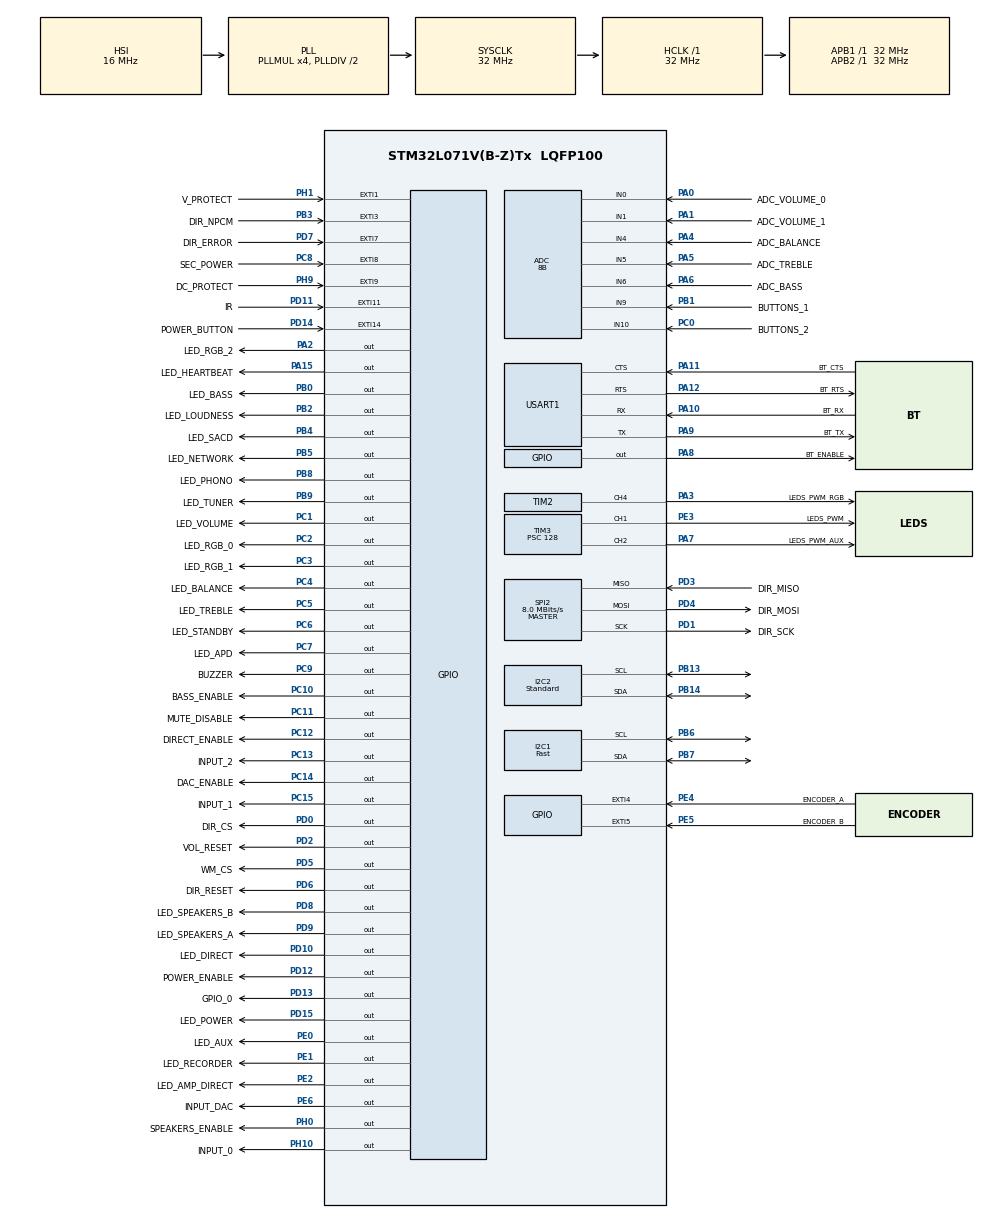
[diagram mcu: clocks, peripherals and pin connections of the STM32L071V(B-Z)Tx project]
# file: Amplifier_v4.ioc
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ADC.ClockPrescaler=ADC_CLOCK_SYNC_PCLK_DIV4
ADC.LowPowerAutoWait=ENABLE
ADC.Overrun=ADC_OVR_DATA_OVERWRITTEN
ADC.OversamplingMode=DISABLE
ADC.Resolution=ADC_RESOLUTION_8B
ADC.SamplingTime=ADC_SAMPLETIME_79CYCLES_5
I2C1.Analog_Filter=I2C_ANALOGFILTER_DISABLE
I2C1.I2C_Speed_Mode=I2C_Fast
I2C1.Timing=0x00301139
I2C2.Analog_Filter=I2C_ANALOGFILTER_ENABLE
I2C2.I2C_Speed_Mode=I2C_Standard
I2C2.Timing=0x00707CBB
Mcu.Family=STM32L0
Mcu.Name=STM32L071V(B-Z)Tx
Mcu.Package=LQFP100
NVIC.ADC1_COMP_IRQn=true\:2\:0\:true\:false\:true\:true\:true
NVIC.EXTI0_1_IRQn=true\:0\:0\:true\:false\:true\:true\:true
NVIC.EXTI2_3_IRQn=true\:0\:0\:false\:false\:true\:true\:true
NVIC.EXTI4_15_IRQn=true\:0\:0\:true\:false\:true\:true\:true
NVIC.TIM6_IRQn=true\:1\:0\:true\:false\:true\:true\:true
NVIC.TIM7_IRQn=true\:1\:0\:true\:false\:true\:true\:true
NVIC.USART1_IRQn=true\:1\:0\:true\:false\:true\:true\:true
PA0.GPIO_Label=ADC_VOLUME_0
PA0.Mode=IN0
PA0.Signal=ADC_IN0
PA1.GPIO_Label=ADC_VOLUME_1
PA1.Mode=IN1
PA1.Signal=ADC_IN1
PA10.GPIO_Label=BT_RX
PA10.Mode=Asynchronous
PA10.Signal=USART1_RX
PA11.GPIO_Label=BT_CTS
PA11.Mode=CTS_RTS
PA11.Signal=USART1_CTS
PA12.GPIO_Label=BT_RTS
PA12.Mode=CTS_RTS
PA12.Signal=USART1_RTS
PA13.Mode=Serial_Wire
PA13.Signal=SYS_SWDIO
PA14.Mode=Serial_Wire
PA14.Signal=SYS_SWCLK
PA15.GPIO_Label=LED_HEARTBEAT
PA15.Signal=GPIO_Output
PA2.GPIO_Label=LED_RGB_2
PA2.Signal=GPIO_Output
PA3.GPIO_Label=LEDS_PWM_RGB
PA3.Signal=S_TIM2_CH4
PA4.GPIO_Label=ADC_BALANCE
PA4.Mode=IN4
PA4.Signal=ADC_IN4
PA5.GPIO_Label=ADC_TREBLE
PA5.Mode=IN5
PA5.Signal=ADC_IN5
PA6.GPIO_Label=ADC_BASS
PA6.Mode=IN6
PA6.Signal=ADC_IN6
PA7.GPIO_Label=LEDS_PWM_AUX
PA7.Signal=S_TIM3_CH2
PA8.GPIO_Label=BT_ENABLE
PA8.PinState=GPIO_PIN_SET
PA8.Signal=GPIO_Output
PA9.GPIO_Label=BT_TX
PA9.Mode=Asynchronous
PA9.Signal=USART1_TX
PB0.GPIO_Label=LED_BASS
PB0.Signal=GPIO_Output
PB1.GPIO_Label=BUTTONS_1
PB1.Mode=IN9
PB1.Signal=ADC_IN9
PB13.Mode=I2C
PB13.Signal=I2C2_SCL
PB14.Mode=I2C
PB14.Signal=I2C2_SDA
PB2.GPIO_Label=LED_LOUDNESS
PB2.Signal=GPIO_Output
PB3.GPIO_Label=DIR_NPCM
PB3.GPIO_ModeDefaultEXTI=GPIO_MODE_IT_RISING_FALLING
PB3.Signal=GPXTI3
PB4.GPIO_Label=LED_SACD
PB4.Signal=GPIO_Output
PB5.GPIO_Label=LED_NETWORK
PB5.Signal=GPIO_Output
PB6.Mode=I2C
PB6.Signal=I2C1_SCL
PB7.Mode=I2C
PB7.Signal=I2C1_SDA
PB8.GPIO_Label=LED_PHONO
PB8.Signal=GPIO_Output
PB9.GPIO_Label=LED_TUNER
PB9.Signal=GPIO_Output
PC0.GPIO_Label=BUTTONS_2
PC0.Mode=IN10
PC0.Signal=ADC_IN10
PC1.GPIO_Label=LED_VOLUME
PC1.Signal=GPIO_Output
PC10.GPIO_Label=BASS_ENABLE
PC10.Signal=GPIO_Output
PC11.GPIO_Label=MUTE_DISABLE
PC11.Signal=GPIO_Output
PC12.GPIO_Label=DIRECT_ENABLE
PC12.Signal=GPIO_Output
PC13.GPIO_Label=INPUT_2
PC13.Signal=GPIO_Output
PC14-OSC32_IN.GPIO_Label=DAC_ENABLE
PC14-OSC32_IN.Signal=GPIO_Output
PC15-OSC32_OUT.GPIO_Label=INPUT_1
PC15-OSC32_OUT.Signal=GPIO_Output
PC2.GPIO_Label=LED_RGB_0
PC2.Signal=GPIO_Output
PC3.GPIO_Label=LED_RGB_1
PC3.Signal=GPIO_Output
PC4.GPIO_Label=LED_BALANCE
PC4.Signal=GPIO_Output
PC5.GPIO_Label=LED_TREBLE
PC5.Signal=GPIO_Output
PC6.GPIO_Label=LED_STANDBY
PC6.Signal=GPIO_Output
PC7.GPIO_Label=LED_APD
PC7.Signal=GPIO_Output
PC8.GPIO_Label=SEC_POWER
PC8.Signal=GPXTI8
PC9.GPIO_Label=BUZZER
PC9.Signal=GPIO_Output
PD0.GPIO_Label=DIR_CS
PD0.Signal=GPIO_Output
PD1.GPIO_Label=DIR_SCK
PD1.Mode=Full_Duplex_Master
PD1.Signal=SPI2_SCK
PD10.GPIO_Label=LED_DIRECT
PD10.Signal=GPIO_Output
PD11.GPIO_Label=IR
PD11.GPIO_ModeDefaultEXTI=GPIO_MODE_IT_FALLING
PD11.Signal=GPXTI11
PD12.GPIO_Label=POWER_ENABLE
PD12.Signal=GPIO_Output
PD13.GPIO_Label=GPIO_0
PD13.Signal=GPIO_Output
PD14.GPIO_Label=POWER_BUTTON
PD14.GPIO_ModeDefaultEXTI=GPIO_MODE_IT_RISING_FALLING
PD14.Signal=GPXTI14
PD15.GPIO_Label=LED_POWER
PD15.Signal=GPIO_Output
PD2.GPIO_Label=VOL_RESET
PD2.Signal=GPIO_Output
PD3.GPIO_Label=DIR_MISO
PD3.Mode=Full_Duplex_Master
PD3.Signal=SPI2_MISO
PD4.GPIO_Label=DIR_MOSI
PD4.Mode=Full_Duplex_Master
PD4.Signal=SPI2_MOSI
PD5.GPIO_Label=WM_CS
PD5.Signal=GPIO_Output
PD6.GPIO_Label=DIR_RESET
PD6.Signal=GPIO_Output
PD7.GPIO_Label=DIR_ERROR
PD7.Signal=GPXTI7
PD8.GPIO_Label=LED_SPEAKERS_B
PD8.Signal=GPIO_Output
PD9.GPIO_Label=LED_SPEAKERS_A
PD9.Signal=GPIO_Output
PE0.GPIO_Label=LED_AUX
PE0.Signal=GPIO_Output
PE1.GPIO_Label=LED_RECORDER
PE1.Signal=GPIO_Output
PE2.GPIO_Label=LED_AMP_DIRECT
PE2.Signal=GPIO_Output
PE3.GPIO_Label=LEDS_PWM
PE3.Signal=S_TIM3_CH1
PE4.GPIO_Label=ENCODER_A
PE4.GPIO_ModeDefaultEXTI=GPIO_MODE_IT_RISING_FALLING
PE4.Signal=GPXTI4
PE5.GPIO_Label=ENCODER_B
PE5.GPIO_ModeDefaultEXTI=GPIO_MODE_IT_RISING_FALLING
PE5.Signal=GPXTI5
PE6.GPIO_Label=INPUT_DAC
PE6.Signal=GPIO_Output
PH0-OSC_IN.GPIO_Label=SPEAKERS_ENABLE
PH0-OSC_IN.Signal=GPIO_Output
PH1-OSC_OUT.GPIO_Label=V_PROTECT
PH1-OSC_OUT.GPIO_ModeDefaultEXTI=GPIO_MODE_IT_FALLING
PH1-OSC_OUT.Signal=GPXTI1
PH10.GPIO_Label=INPUT_0
PH10.Signal=GPIO_Output
PH9.GPIO_Label=DC_PROTECT
PH9.GPIO_ModeDefaultEXTI=GPIO_MODE_IT_FALLING
PH9.Signal=GPXTI9
ProjectManager.HeapSize=0x200
ProjectManager.StackSize=0x400
ProjectManager.TargetToolchain=STM32CubeIDE
RCC.ADCFreq_Value=16000000
RCC.AHBFreq_Value=32000000
RCC.APB1Freq_Value=32000000
RCC.APB1TimFreq_Value=32000000
RCC.APB2Freq_Value=32000000
RCC.APB2TimFreq_Value=32000000
RCC.HCLKFreq_Value=32000000
RCC.HSE_VALUE=8000000
RCC.HSI16_VALUE=16000000
RCC.HSI_VALUE=16000000
RCC.LSE_VALUE=32768
RCC.MSIClockRange=RCC_MSIRANGE_6
RCC.MSI_VALUE=4194000
RCC.PLLMUL=RCC_PLLMUL_4
RCC.SYSCLKFreq_VALUE=32000000
RCC.SYSCLKSource=RCC_SYSCLKSOURCE_PLLCLK
RCC.VCOOutputFreq_Value=64000000
SH.S_TIM2_CH4.0=TIM2_CH4,PWM Generation4 CH4
SH.S_TIM3_CH1.0=TIM3_CH1,PWM Generation1 CH1
SH.S_TIM3_CH2.0=TIM3_CH2,PWM Generation2 CH2
SPI2.BaudRatePrescaler=SPI_BAUDRATEPRESCALER_4
SPI2.CLKPolarity=SPI_POLARITY_LOW
SPI2.CalculateBaudRate=8.0 MBits/s
SPI2.Direction=SPI_DIRECTION_2LINES
SPI2.Mode=SPI_MODE_MASTER
SPI2.VirtualType=VM_MASTER
TIM2.Channel-PWM\ Generation4\ CH4=TIM_CHANNEL_4
TIM2.Period=255
TIM2.Prescaler=2
TIM2.Pulse-PWM\ Generation4\ CH4=127
TIM3.Channel-PWM\ Generation1\ CH1=TIM_CHANNEL_1
TIM3.Channel-PWM\ Generation2\ CH2=TIM_CHANNEL_2
TIM3.OCFastMode_PWM-PWM\ Generation1\ CH1=TIM_OCFAST_ENABLE
TIM3.OCFastMode_PWM-PWM\ Generation2\ CH2=TIM_OCFAST_ENABLE
TIM3.Period=255
TIM3.Prescaler=128
TIM3.Pulse-PWM\ Generation1\ CH1=127
TIM3.Pulse-PWM\ Generation2\ CH2=127
TIM6.AutoReloadPreload=TIM_AUTORELOAD_PRELOAD_ENABLE
TIM6.Period=200
TIM6.Prescaler=1600
TIM7.AutoReloadPreload=TIM_AUTORELOAD_PRELOAD_ENABLE
TIM7.Period=20
TIM7.Prescaler=160
USART1.VirtualMode-Asynchronous=VM_ASYNC
VP_TIM2_VS_ClockSourceINT.Mode=Internal
VP_TIM3_VS_ClockSourceINT.Mode=Internal
VP_TIM6_VS_ClockSourceINT.Mode=Enable_Timer
VP_TIM7_VS_ClockSourceINT.Mode=Enable_Timer
board=custom

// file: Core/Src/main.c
/* USER CODE BEGIN Header */
/**
  ******************************************************************************
  * @file           : main.c
  * @brief          : Main program body
  ******************************************************************************
  * @attention
  *
  * <h2><center>&copy; Copyright (c) 2021 STMicroelectronics.
  * All rights reserved.</center></h2>
  *
  * This software component is licensed by ST under BSD 3-Clause license,
  * the "License"; You may not use this file except in compliance with the
  * License. You may obtain a copy of the License at:
  *                        opensource.org/licenses/BSD-3-Clause
  *
  ******************************************************************************
  */
/* USER CODE END Header */
#include "main.h"

/* USER CODE BEGIN Includes */
#include "system.h"
#include "heartbeat.h"
#include "led.h"
#include "buzzer.h"
#include "adc.h"
#include "encoder.h"
#include "input.h"
#include "potentiometer.h"
#include "protection.h"
#include "buttons.h"
#include "ir_nec.h"
#include "amplifier.h"
#include "mcp23008.h"
#include "dac.h"
#include "tmp100.h"
#include "uart.h"
#include "calibrator.h"
/* USER CODE END Includes */

/* USER CODE BEGIN PTD */
//#define USE_FULL_ASSERT
/* USER CODE END PTD */

ADC_HandleTypeDef hadc;

I2C_HandleTypeDef hi2c1;
I2C_HandleTypeDef hi2c2;

SPI_HandleTypeDef hspi2;

TIM_HandleTypeDef htim2;
TIM_HandleTypeDef htim3;
TIM_HandleTypeDef htim6;
TIM_HandleTypeDef htim7;

UART_HandleTypeDef huart1;

void SystemClock_Config(void);
static void MX_GPIO_Init(void);
static void MX_TIM3_Init(void);
static void MX_ADC_Init(void);
static void MX_TIM2_Init(void);
static void MX_I2C2_Init(void);
static void MX_USART1_UART_Init(void);
static void MX_SPI2_Init(void);
static void MX_I2C1_Init(void);
static void MX_TIM6_Init(void);
static void MX_TIM7_Init(void);

/* USER CODE BEGIN 0 */
void HAL_UART_RxCpltCallback(UART_HandleTypeDef *huart)
{
	UART_Store();
	HAL_UART_Receive_IT(&huart1, uartHandler.rxByte, UART_RX_SIZE);
}

void HAL_UART_ErrorCallback(UART_HandleTypeDef *huart)
{
	/*HAL_UART_DeInit(&huart1);
	HAL_Delay(10);
	HAL_UART_Init(&huart1);*/
	uartHandler.rxDataReady = 0;
	uartHandler.rxIndex = 0;
}

void HAL_TIM_PeriodElapsedCallback(TIM_HandleTypeDef *htim)
{
	if (htim == &htim6)
	{
		buttons.timer++;
		encoder.timer++;
		potentiometers.timer++;
		input.npcmTimer++;
		input.muteTimer++;
		temperature.timer++;
		HEARTBEAT_Process();
	}
	else if (htim == &htim7)
	{
		IR_ProcessTimer();
	}
}

void HAL_GPIO_EXTI_Callback(uint16_t GPIO_Pin)
{
	switch (GPIO_Pin)
	{
		// IR
		case IR_PIN: {
			IR_Encode();
		} break;

		// POWER
		case POWER_PIN: {
			if (EXTI->FTSR & POWER_PIN)
			{
				CLEAR_BIT(EXTI->FTSR, POWER_PIN);
				SET_BIT(EXTI->RTSR, POWER_PIN);
				buttons.power.time = buttons.timer;
				buttons.power.state = Pressed;
			}
			else if (EXTI->RTSR & POWER_PIN)
			{
				CLEAR_BIT(EXTI->RTSR, POWER_PIN);
				buttons.power.state = Released;

				if (BUTTONS_PressValid(buttons.power.time, BUTTON_LONG_HOLD_TIME))
				{
					for (uint32_t i = 0; i < 4; i++)
					{
						LED_Standby(GPIO_PIN_SET);
						HAL_Delay(200);
						LED_Standby(GPIO_PIN_RESET);
						HAL_Delay(200);
					}
					PROTECTION_Reset();
				}
				if (BUTTONS_PressValid(buttons.power.time, BUTTON_PRESSED_TIME))
				{
					AMP_PowerToggle();
				}
				buttons.power.time = buttons.timer;
				SET_BIT(EXTI->FTSR, POWER_PIN);
			}
		} break;

		// ENCODER
		case ENCODER_A_PIN:
		case ENCODER_B_PIN: {
			if (system.power.state == On) {
				ENCODER_Encode(GPIO_Pin);
			}
		} break;

		// PROTECTION
		case DC_PIN: {
			if (system.power.state == On) {
				system.states.protectionTriggeredDc = 1;
			}
		} break;

		case V_PIN: {
			if (system.power.state == On) {
				system.states.protectionTriggeredVoltage = 1;
			}
		} break;

		// PCM9211
		case PCM9211_NPCM_PIN: {
			if (system.power.state == On) {
				dac.npcm = 1;
			}
		} break;

		case PCM9211_ERROR_PIN: {
			if (system.power.state == On) {
				dac.error = 1;
			}
		} break;

		default:
		{

		} break;

	}
}

void HAL_ADC_ConvCpltCallback(ADC_HandleTypeDef* phadc)
{
	if (__HAL_ADC_GET_FLAG(phadc, ADC_FLAG_EOC))
	{
		ADC_StoreValue(HAL_ADC_GetValue(phadc));
	}

	if (__HAL_ADC_GET_FLAG(phadc, ADC_FLAG_EOS))
	{
		ADC_Finalize();
	}

	HAL_ADC_Start_IT(phadc);
}

/* USER CODE END 0 */

int main(void)
{

  /* MCU Configuration--------------------------------------------------------*/

  /* Reset of all peripherals, Initializes the Flash interface and the Systick. */
  HAL_Init();

  /* Configure the system clock */
  SystemClock_Config();

  /* Initialize all configured peripherals */
  MX_GPIO_Init();
  MX_TIM3_Init();
  MX_ADC_Init();
  MX_TIM2_Init();
  MX_I2C2_Init();
  MX_USART1_UART_Init();
  MX_SPI2_Init();
  MX_I2C1_Init();
  MX_TIM6_Init();
  MX_TIM7_Init();
  /* USER CODE BEGIN 2 */

  // INITIALIZE
  // SYSTEM
  SYSTEM_Initialize();
  SYSTEM_InitializePower();
  SYSTEM_InitializeValues();
  // PROTECTION
  PROTECTION_Initialize();
  // LED
  LED_Initialize(&htim3);
  // BUZZER
  //BUZZER_PowerOn();
  // ADC
  ADC_Initialize();
  HAL_ADC_Start_IT(&hadc);
  // ENCODER | 40 * 10ms = 0.4s
  ENCODER_Initialize(40, INPUT_Changed, INPUT_Confirmed);
  // INPUT
  INPUT_Initialize();
  // POTENTIOMETERS
  POTENTIOMETERS_Initialize();
  // IR
  IR_Initialize();
  // MCP23008
  MCP23008_Init(&hi2c1);
  // DAC
  DAC_Initialize(&hspi2);
  // TMP100
  TMP100_Init(&hi2c2);
  // UART
  UART_Init(&huart1);
  HAL_UART_Receive_IT(&huart1, uartHandler.rxByte, UART_RX_SIZE);
#ifdef USE_CALIBRATOR
  // CALIBRATOR (Needs to initialize only for pot calibrations.)
  CALIBRATOR_Initialize();
#endif
  // START TIMERS
  HAL_TIM_Base_Start_IT(&htim7);
  HAL_TIM_Base_Start_IT(&htim6);

  /* USER CODE END 2 */

  /* Infinite loop */
  /* USER CODE BEGIN WHILE */
  while (1)
  {
	IR_Process();

	if (uartHandler.rxDataReady)
	{
		UART_Process();
		uartHandler.rxDataReady = 0;
	}

	if (system.power.state == On)
	{
		PROTECTION_Process();
		ENCODER_Process();
		POTENTIOMETERS_Process();

		if (adc.dataReady)
		{
			adc.dataReady = 0;
			if (system.power.state == On)
			{
				BUTTONS_ProcessADC_MainGroup(adc.data[5]);
				BUTTONS_ProcessADC_SelectorGroup(adc.data[6]);
				POTENTIOMETERS_SetCurrent(adc.data[0], adc.data[4], adc.data[3], adc.data[2]);
			}
		}

#ifdef USE_CALIBRATOR
	    CALIBRATOR_Process(); // (Needs to run only for pot calibrations.)
#endif

		DAC_Process();
		INPUT_Process();

		TMP100_Process();
	}

	AMP_ProcessPower();

    /* USER CODE END WHILE */

  }
}

void SystemClock_Config(void)
{
  RCC_OscInitTypeDef RCC_OscInitStruct = {0};
  RCC_ClkInitTypeDef RCC_ClkInitStruct = {0};
  RCC_PeriphCLKInitTypeDef PeriphClkInit = {0};

  /** Configure the main internal regulator output voltage
  */
  __HAL_PWR_VOLTAGESCALING_CONFIG(PWR_REGULATOR_VOLTAGE_SCALE1);
  /** Initializes the RCC Oscillators according to the specified parameters
  * in the RCC_OscInitTypeDef structure.
  */
  RCC_OscInitStruct.OscillatorType = RCC_OSCILLATORTYPE_HSI;
  RCC_OscInitStruct.HSIState = RCC_HSI_ON;
  RCC_OscInitStruct.HSICalibrationValue = RCC_HSICALIBRATION_DEFAULT;
  RCC_OscInitStruct.PLL.PLLState = RCC_PLL_ON;
  RCC_OscInitStruct.PLL.PLLSource = RCC_PLLSOURCE_HSI;
  RCC_OscInitStruct.PLL.PLLMUL = RCC_PLLMUL_4;
  RCC_OscInitStruct.PLL.PLLDIV = RCC_PLLDIV_2;
  if (HAL_RCC_OscConfig(&RCC_OscInitStruct) != HAL_OK)
  {
    Error_Handler();
  }
  /** Initializes the CPU, AHB and APB buses clocks
  */
  RCC_ClkInitStruct.ClockType = RCC_CLOCKTYPE_HCLK|RCC_CLOCKTYPE_SYSCLK
                              |RCC_CLOCKTYPE_PCLK1|RCC_CLOCKTYPE_PCLK2;
  RCC_ClkInitStruct.SYSCLKSource = RCC_SYSCLKSOURCE_PLLCLK;
  RCC_ClkInitStruct.AHBCLKDivider = RCC_SYSCLK_DIV1;
  RCC_ClkInitStruct.APB1CLKDivider = RCC_HCLK_DIV1;
  RCC_ClkInitStruct.APB2CLKDivider = RCC_HCLK_DIV1;

  if (HAL_RCC_ClockConfig(&RCC_ClkInitStruct, FLASH_LATENCY_1) != HAL_OK)
  {
    Error_Handler();
  }
  PeriphClkInit.PeriphClockSelection = RCC_PERIPHCLK_USART1|RCC_PERIPHCLK_I2C1;
  PeriphClkInit.Usart1ClockSelection = RCC_USART1CLKSOURCE_PCLK2;
  PeriphClkInit.I2c1ClockSelection = RCC_I2C1CLKSOURCE_PCLK1;
  if (HAL_RCCEx_PeriphCLKConfig(&PeriphClkInit) != HAL_OK)
  {
    Error_Handler();
  }
}

static void MX_ADC_Init(void)
{

  ADC_ChannelConfTypeDef sConfig = {0};

  /** Configure the global features of the ADC (Clock, Resolution, Data Alignment and number of conversion)
  */
  hadc.Instance = ADC1;
  hadc.Init.OversamplingMode = DISABLE;
  hadc.Init.ClockPrescaler = ADC_CLOCK_SYNC_PCLK_DIV4;
  hadc.Init.Resolution = ADC_RESOLUTION_8B;
  hadc.Init.SamplingTime = ADC_SAMPLETIME_79CYCLES_5;
  hadc.Init.ScanConvMode = ADC_SCAN_DIRECTION_FORWARD;
  hadc.Init.DataAlign = ADC_DATAALIGN_RIGHT;
  hadc.Init.ContinuousConvMode = DISABLE;
  hadc.Init.DiscontinuousConvMode = DISABLE;
  hadc.Init.ExternalTrigConvEdge = ADC_EXTERNALTRIGCONVEDGE_NONE;
  hadc.Init.ExternalTrigConv = ADC_SOFTWARE_START;
  hadc.Init.DMAContinuousRequests = DISABLE;
  hadc.Init.EOCSelection = ADC_EOC_SINGLE_CONV;
  hadc.Init.Overrun = ADC_OVR_DATA_OVERWRITTEN;
  hadc.Init.LowPowerAutoWait = ENABLE;
  hadc.Init.LowPowerFrequencyMode = DISABLE;
  hadc.Init.LowPowerAutoPowerOff = DISABLE;
  if (HAL_ADC_Init(&hadc) != HAL_OK)
  {
    Error_Handler();
  }
  /** Configure for the selected ADC regular channel to be converted.
  */
  sConfig.Channel = ADC_CHANNEL_0;
  sConfig.Rank = ADC_RANK_CHANNEL_NUMBER;
  if (HAL_ADC_ConfigChannel(&hadc, &sConfig) != HAL_OK)
  {
    Error_Handler();
  }
  /** Configure for the selected ADC regular channel to be converted.
  */
  sConfig.Channel = ADC_CHANNEL_1;
  if (HAL_ADC_ConfigChannel(&hadc, &sConfig) != HAL_OK)
  {
    Error_Handler();
  }
  /** Configure for the selected ADC regular channel to be converted.
  */
  sConfig.Channel = ADC_CHANNEL_4;
  if (HAL_ADC_ConfigChannel(&hadc, &sConfig) != HAL_OK)
  {
    Error_Handler();
  }
  /** Configure for the selected ADC regular channel to be converted.
  */
  sConfig.Channel = ADC_CHANNEL_5;
  if (HAL_ADC_ConfigChannel(&hadc, &sConfig) != HAL_OK)
  {
    Error_Handler();
  }
  /** Configure for the selected ADC regular channel to be converted.
  */
  sConfig.Channel = ADC_CHANNEL_6;
  if (HAL_ADC_ConfigChannel(&hadc, &sConfig) != HAL_OK)
  {
    Error_Handler();
  }
  /** Configure for the selected ADC regular channel to be converted.
  */
  sConfig.Channel = ADC_CHANNEL_9;
  if (HAL_ADC_ConfigChannel(&hadc, &sConfig) != HAL_OK)
  {
    Error_Handler();
  }
  /** Configure for the selected ADC regular channel to be converted.
  */
  sConfig.Channel = ADC_CHANNEL_10;
  if (HAL_ADC_ConfigChannel(&hadc, &sConfig) != HAL_OK)
  {
    Error_Handler();
  }

}

static void MX_I2C1_Init(void)
{

  hi2c1.Instance = I2C1;
  hi2c1.Init.Timing = 0x00301139;
  hi2c1.Init.OwnAddress1 = 0;
  hi2c1.Init.AddressingMode = I2C_ADDRESSINGMODE_7BIT;
  hi2c1.Init.DualAddressMode = I2C_DUALADDRESS_DISABLE;
  hi2c1.Init.OwnAddress2 = 0;
  hi2c1.Init.OwnAddress2Masks = I2C_OA2_NOMASK;
  hi2c1.Init.GeneralCallMode = I2C_GENERALCALL_DISABLE;
  hi2c1.Init.NoStretchMode = I2C_NOSTRETCH_DISABLE;
  if (HAL_I2C_Init(&hi2c1) != HAL_OK)
  {
    Error_Handler();
  }
  /** Configure Analogue filter
  */
  if (HAL_I2CEx_ConfigAnalogFilter(&hi2c1, I2C_ANALOGFILTER_DISABLE) != HAL_OK)
  {
    Error_Handler();
  }
  /** Configure Digital filter
  */
  if (HAL_I2CEx_ConfigDigitalFilter(&hi2c1, 0) != HAL_OK)
  {
    Error_Handler();
  }

}

static void MX_I2C2_Init(void)
{

  hi2c2.Instance = I2C2;
  hi2c2.Init.Timing = 0x00707CBB;
  hi2c2.Init.OwnAddress1 = 0;
  hi2c2.Init.AddressingMode = I2C_ADDRESSINGMODE_7BIT;
  hi2c2.Init.DualAddressMode = I2C_DUALADDRESS_DISABLE;
  hi2c2.Init.OwnAddress2 = 0;
  hi2c2.Init.OwnAddress2Masks = I2C_OA2_NOMASK;
  hi2c2.Init.GeneralCallMode = I2C_GENERALCALL_DISABLE;
  hi2c2.Init.NoStretchMode = I2C_NOSTRETCH_DISABLE;
  if (HAL_I2C_Init(&hi2c2) != HAL_OK)
  {
    Error_Handler();
  }
  /** Configure Analogue filter
  */
  if (HAL_I2CEx_ConfigAnalogFilter(&hi2c2, I2C_ANALOGFILTER_ENABLE) != HAL_OK)
  {
    Error_Handler();
  }
  /** Configure Digital filter
  */
  if (HAL_I2CEx_ConfigDigitalFilter(&hi2c2, 0) != HAL_OK)
  {
    Error_Handler();
  }

}

static void MX_SPI2_Init(void)
{

  /* SPI2 parameter configuration*/
  hspi2.Instance = SPI2;
  hspi2.Init.Mode = SPI_MODE_MASTER;
  hspi2.Init.Direction = SPI_DIRECTION_2LINES;
  hspi2.Init.DataSize = SPI_DATASIZE_8BIT;
  hspi2.Init.CLKPolarity = SPI_POLARITY_LOW;
  hspi2.Init.CLKPhase = SPI_PHASE_1EDGE;
  hspi2.Init.NSS = SPI_NSS_SOFT;
  hspi2.Init.BaudRatePrescaler = SPI_BAUDRATEPRESCALER_4;
  hspi2.Init.FirstBit = SPI_FIRSTBIT_MSB;
  hspi2.Init.TIMode = SPI_TIMODE_DISABLE;
  hspi2.Init.CRCCalculation = SPI_CRCCALCULATION_DISABLE;
  hspi2.Init.CRCPolynomial = 7;
  if (HAL_SPI_Init(&hspi2) != HAL_OK)
  {
    Error_Handler();
  }

}

static void MX_TIM2_Init(void)
{

  TIM_ClockConfigTypeDef sClockSourceConfig = {0};
  TIM_MasterConfigTypeDef sMasterConfig = {0};
  TIM_OC_InitTypeDef sConfigOC = {0};

  htim2.Instance = TIM2;
  htim2.Init.Prescaler = 2;
  htim2.Init.CounterMode = TIM_COUNTERMODE_UP;
  htim2.Init.Period = 255;
  htim2.Init.ClockDivision = TIM_CLOCKDIVISION_DIV1;
  htim2.Init.AutoReloadPreload = TIM_AUTORELOAD_PRELOAD_DISABLE;
  if (HAL_TIM_Base_Init(&htim2) != HAL_OK)
  {
    Error_Handler();
  }
  sClockSourceConfig.ClockSource = TIM_CLOCKSOURCE_INTERNAL;
  if (HAL_TIM_ConfigClockSource(&htim2, &sClockSourceConfig) != HAL_OK)
  {
    Error_Handler();
  }
  if (HAL_TIM_PWM_Init(&htim2) != HAL_OK)
  {
    Error_Handler();
  }
  sMasterConfig.MasterOutputTrigger = TIM_TRGO_RESET;
  sMasterConfig.MasterSlaveMode = TIM_MASTERSLAVEMODE_DISABLE;
  if (HAL_TIMEx_MasterConfigSynchronization(&htim2, &sMasterConfig) != HAL_OK)
  {
    Error_Handler();
  }
  sConfigOC.OCMode = TIM_OCMODE_PWM1;
  sConfigOC.Pulse = 127;
  sConfigOC.OCPolarity = TIM_OCPOLARITY_HIGH;
  sConfigOC.OCFastMode = TIM_OCFAST_DISABLE;
  if (HAL_TIM_PWM_ConfigChannel(&htim2, &sConfigOC, TIM_CHANNEL_4) != HAL_OK)
  {
    Error_Handler();
  }
  HAL_TIM_MspPostInit(&htim2);

}

static void MX_TIM3_Init(void)
{

  TIM_ClockConfigTypeDef sClockSourceConfig = {0};
  TIM_MasterConfigTypeDef sMasterConfig = {0};
  TIM_OC_InitTypeDef sConfigOC = {0};

  htim3.Instance = TIM3;
  htim3.Init.Prescaler = 128;
  htim3.Init.CounterMode = TIM_COUNTERMODE_UP;
  htim3.Init.Period = 255;
  htim3.Init.ClockDivision = TIM_CLOCKDIVISION_DIV1;
  htim3.Init.AutoReloadPreload = TIM_AUTORELOAD_PRELOAD_DISABLE;
  if (HAL_TIM_Base_Init(&htim3) != HAL_OK)
  {
    Error_Handler();
  }
  sClockSourceConfig.ClockSource = TIM_CLOCKSOURCE_INTERNAL;
  if (HAL_TIM_ConfigClockSource(&htim3, &sClockSourceConfig) != HAL_OK)
  {
    Error_Handler();
  }
  if (HAL_TIM_PWM_Init(&htim3) != HAL_OK)
  {
    Error_Handler();
  }
  sMasterConfig.MasterOutputTrigger = TIM_TRGO_RESET;
  sMasterConfig.MasterSlaveMode = TIM_MASTERSLAVEMODE_DISABLE;
  if (HAL_TIMEx_MasterConfigSynchronization(&htim3, &sMasterConfig) != HAL_OK)
  {
    Error_Handler();
  }
  sConfigOC.OCMode = TIM_OCMODE_PWM1;
  sConfigOC.Pulse = 127;
  sConfigOC.OCPolarity = TIM_OCPOLARITY_HIGH;
  sConfigOC.OCFastMode = TIM_OCFAST_ENABLE;
  if (HAL_TIM_PWM_ConfigChannel(&htim3, &sConfigOC, TIM_CHANNEL_1) != HAL_OK)
  {
    Error_Handler();
  }
  if (HAL_TIMEx_RemapConfig(&htim3, TIM3_TI1_GPIO) != HAL_OK)
  {
    Error_Handler();
  }
  if (HAL_TIM_PWM_ConfigChannel(&htim3, &sConfigOC, TIM_CHANNEL_2) != HAL_OK)
  {
    Error_Handler();
  }
  HAL_TIM_MspPostInit(&htim3);

}

static void MX_TIM6_Init(void)
{

  TIM_MasterConfigTypeDef sMasterConfig = {0};

  htim6.Instance = TIM6;
  htim6.Init.Prescaler = 1600;
  htim6.Init.CounterMode = TIM_COUNTERMODE_UP;
  htim6.Init.Period = 200;
  htim6.Init.AutoReloadPreload = TIM_AUTORELOAD_PRELOAD_ENABLE;
  if (HAL_TIM_Base_Init(&htim6) != HAL_OK)
  {
    Error_Handler();
  }
  sMasterConfig.MasterOutputTrigger = TIM_TRGO_RESET;
  sMasterConfig.MasterSlaveMode = TIM_MASTERSLAVEMODE_DISABLE;
  if (HAL_TIMEx_MasterConfigSynchronization(&htim6, &sMasterConfig) != HAL_OK)
  {
    Error_Handler();
  }

}

static void MX_TIM7_Init(void)
{

  TIM_MasterConfigTypeDef sMasterConfig = {0};

  htim7.Instance = TIM7;
  htim7.Init.Prescaler = 160;
  htim7.Init.CounterMode = TIM_COUNTERMODE_UP;
  htim7.Init.Period = 20;
  htim7.Init.AutoReloadPreload = TIM_AUTORELOAD_PRELOAD_ENABLE;
  if (HAL_TIM_Base_Init(&htim7) != HAL_OK)
  {
    Error_Handler();
  }
  sMasterConfig.MasterOutputTrigger = TIM_TRGO_RESET;
  sMasterConfig.MasterSlaveMode = TIM_MASTERSLAVEMODE_DISABLE;
  if (HAL_TIMEx_MasterConfigSynchronization(&htim7, &sMasterConfig) != HAL_OK)
  {
    Error_Handler();
  }

}

static void MX_USART1_UART_Init(void)
{

  huart1.Instance = USART1;
  huart1.Init.BaudRate = 115200;
  huart1.Init.WordLength = UART_WORDLENGTH_8B;
  huart1.Init.StopBits = UART_STOPBITS_1;
  huart1.Init.Parity = UART_PARITY_NONE;
  huart1.Init.Mode = UART_MODE_TX_RX;
  huart1.Init.HwFlowCtl = UART_HWCONTROL_RTS_CTS;
  huart1.Init.OverSampling = UART_OVERSAMPLING_16;
  huart1.Init.OneBitSampling = UART_ONE_BIT_SAMPLE_DISABLE;
  huart1.AdvancedInit.AdvFeatureInit = UART_ADVFEATURE_NO_INIT;
  if (HAL_UART_Init(&huart1) != HAL_OK)
  {
    Error_Handler();
  }

}

static void MX_GPIO_Init(void)
{
  GPIO_InitTypeDef GPIO_InitStruct = {0};

  /* GPIO Ports Clock Enable */
  __HAL_RCC_GPIOE_CLK_ENABLE();
  __HAL_RCC_GPIOC_CLK_ENABLE();
  __HAL_RCC_GPIOH_CLK_ENABLE();
  __HAL_RCC_GPIOA_CLK_ENABLE();
  __HAL_RCC_GPIOB_CLK_ENABLE();
  __HAL_RCC_GPIOD_CLK_ENABLE();

  /*Configure GPIO pin Output Level */
  HAL_GPIO_WritePin(GPIOE, LED_AMP_DIRECT_Pin|INPUT_DAC_Pin|LED_AUX_Pin|LED_RECORDER_Pin, GPIO_PIN_RESET);

  /*Configure GPIO pin Output Level */
  HAL_GPIO_WritePin(GPIOC, INPUT_2_Pin|DAC_ENABLE_Pin|INPUT_1_Pin|LED_VOLUME_Pin
                          |LED_RGB_0_Pin|LED_RGB_1_Pin|LED_BALANCE_Pin|LED_TREBLE_Pin
                          |LED_STANDBY_Pin|LED_APD_Pin|BUZZER_Pin|BASS_ENABLE_Pin
                          |MUTE_DISABLE_Pin|DIRECT_ENABLE_Pin, GPIO_PIN_RESET);

  /*Configure GPIO pin Output Level */
  HAL_GPIO_WritePin(GPIOH, INPUT_0_Pin|SPEAKERS_ENABLE_Pin, GPIO_PIN_RESET);

  /*Configure GPIO pin Output Level */
  HAL_GPIO_WritePin(GPIOA, LED_RGB_2_Pin|LED_HEARTBEAT_Pin, GPIO_PIN_RESET);

  /*Configure GPIO pin Output Level */
  HAL_GPIO_WritePin(GPIOB, LED_BASS_Pin|LED_LOUDNESS_Pin|LED_SACD_Pin|LED_NETWORK_Pin
                          |LED_PHONO_Pin|LED_TUNER_Pin, GPIO_PIN_RESET);

  /*Configure GPIO pin Output Level */
  HAL_GPIO_WritePin(GPIOD, LED_SPEAKERS_B_Pin|LED_SPEAKERS_A_Pin|LED_DIRECT_Pin|POWER_ENABLE_Pin
                          |GPIO_0_Pin|LED_POWER_Pin|DIR_CS_Pin|VOL_RESET_Pin
                          |WM_CS_Pin|DIR_RESET_Pin, GPIO_PIN_RESET);

  /*Configure GPIO pin Output Level */
  HAL_GPIO_WritePin(BT_ENABLE_GPIO_Port, BT_ENABLE_Pin, GPIO_PIN_SET);

  /*Configure GPIO pins : LED_AMP_DIRECT_Pin INPUT_DAC_Pin LED_AUX_Pin LED_RECORDER_Pin */
  GPIO_InitStruct.Pin = LED_AMP_DIRECT_Pin|INPUT_DAC_Pin|LED_AUX_Pin|LED_RECORDER_Pin;
  GPIO_InitStruct.Mode = GPIO_MODE_OUTPUT_PP;
  GPIO_InitStruct.Pull = GPIO_NOPULL;
  GPIO_InitStruct.Speed = GPIO_SPEED_FREQ_LOW;
  HAL_GPIO_Init(GPIOE, &GPIO_InitStruct);

  /*Configure GPIO pins : ENCODER_A_Pin ENCODER_B_Pin */
  GPIO_InitStruct.Pin = ENCODER_A_Pin|ENCODER_B_Pin;
  GPIO_InitStruct.Mode = GPIO_MODE_IT_RISING_FALLING;
  GPIO_InitStruct.Pull = GPIO_NOPULL;
  HAL_GPIO_Init(GPIOE, &GPIO_InitStruct);

  /*Configure GPIO pins : INPUT_2_Pin DAC_ENABLE_Pin INPUT_1_Pin LED_VOLUME_Pin
                           LED_RGB_0_Pin LED_RGB_1_Pin LED_BALANCE_Pin LED_TREBLE_Pin
                           LED_STANDBY_Pin LED_APD_Pin BUZZER_Pin BASS_ENABLE_Pin
                           MUTE_DISABLE_Pin DIRECT_ENABLE_Pin */
  GPIO_InitStruct.Pin = INPUT_2_Pin|DAC_ENABLE_Pin|INPUT_1_Pin|LED_VOLUME_Pin
                          |LED_RGB_0_Pin|LED_RGB_1_Pin|LED_BALANCE_Pin|LED_TREBLE_Pin
                          |LED_STANDBY_Pin|LED_APD_Pin|BUZZER_Pin|BASS_ENABLE_Pin
                          |MUTE_DISABLE_Pin|DIRECT_ENABLE_Pin;
  GPIO_InitStruct.Mode = GPIO_MODE_OUTPUT_PP;
  GPIO_InitStruct.Pull = GPIO_NOPULL;
  GPIO_InitStruct.Speed = GPIO_SPEED_FREQ_LOW;
  HAL_GPIO_Init(GPIOC, &GPIO_InitStruct);

  /*Configure GPIO pins : DC_PROTECT_Pin V_PROTECT_Pin */
  GPIO_InitStruct.Pin = DC_PROTECT_Pin|V_PROTECT_Pin;
  GPIO_InitStruct.Mode = GPIO_MODE_IT_FALLING;
  GPIO_InitStruct.Pull = GPIO_NOPULL;
  HAL_GPIO_Init(GPIOH, &GPIO_InitStruct);

  /*Configure GPIO pins : INPUT_0_Pin SPEAKERS_ENABLE_Pin */
  GPIO_InitStruct.Pin = INPUT_0_Pin|SPEAKERS_ENABLE_Pin;
  GPIO_InitStruct.Mode = GPIO_MODE_OUTPUT_PP;
  GPIO_InitStruct.Pull = GPIO_NOPULL;
  GPIO_InitStruct.Speed = GPIO_SPEED_FREQ_LOW;
  HAL_GPIO_Init(GPIOH, &GPIO_InitStruct);

  /*Configure GPIO pins : LED_RGB_2_Pin BT_ENABLE_Pin LED_HEARTBEAT_Pin */
  GPIO_InitStruct.Pin = LED_RGB_2_Pin|BT_ENABLE_Pin|LED_HEARTBEAT_Pin;
  GPIO_InitStruct.Mode = GPIO_MODE_OUTPUT_PP;
  GPIO_InitStruct.Pull = GPIO_NOPULL;
  GPIO_InitStruct.Speed = GPIO_SPEED_FREQ_LOW;
  HAL_GPIO_Init(GPIOA, &GPIO_InitStruct);

  /*Configure GPIO pins : LED_BASS_Pin LED_LOUDNESS_Pin LED_SACD_Pin LED_NETWORK_Pin
                           LED_PHONO_Pin LED_TUNER_Pin */
  GPIO_InitStruct.Pin = LED_BASS_Pin|LED_LOUDNESS_Pin|LED_SACD_Pin|LED_NETWORK_Pin
                          |LED_PHONO_Pin|LED_TUNER_Pin;
  GPIO_InitStruct.Mode = GPIO_MODE_OUTPUT_PP;
  GPIO_InitStruct.Pull = GPIO_NOPULL;
  GPIO_InitStruct.Speed = GPIO_SPEED_FREQ_LOW;
  HAL_GPIO_Init(GPIOB, &GPIO_InitStruct);

  /*Configure GPIO pins : LED_SPEAKERS_B_Pin LED_SPEAKERS_A_Pin LED_DIRECT_Pin POWER_ENABLE_Pin
                           GPIO_0_Pin LED_POWER_Pin DIR_CS_Pin VOL_RESET_Pin
                           WM_CS_Pin DIR_RESET_Pin */
  GPIO_InitStruct.Pin = LED_SPEAKERS_B_Pin|LED_SPEAKERS_A_Pin|LED_DIRECT_Pin|POWER_ENABLE_Pin
                          |GPIO_0_Pin|LED_POWER_Pin|DIR_CS_Pin|VOL_RESET_Pin
                          |WM_CS_Pin|DIR_RESET_Pin;
  GPIO_InitStruct.Mode = GPIO_MODE_OUTPUT_PP;
  GPIO_InitStruct.Pull = GPIO_NOPULL;
  GPIO_InitStruct.Speed = GPIO_SPEED_FREQ_LOW;
  HAL_GPIO_Init(GPIOD, &GPIO_InitStruct);

  /*Configure GPIO pin : IR_Pin */
  GPIO_InitStruct.Pin = IR_Pin;
  GPIO_InitStruct.Mode = GPIO_MODE_IT_FALLING;
  GPIO_InitStruct.Pull = GPIO_NOPULL;
  HAL_GPIO_Init(IR_GPIO_Port, &GPIO_InitStruct);

  /*Configure GPIO pin : POWER_BUTTON_Pin */
  GPIO_InitStruct.Pin = POWER_BUTTON_Pin;
  GPIO_InitStruct.Mode = GPIO_MODE_IT_RISING_FALLING;
  GPIO_InitStruct.Pull = GPIO_NOPULL;
  HAL_GPIO_Init(POWER_BUTTON_GPIO_Port, &GPIO_InitStruct);

  /*Configure GPIO pin : SEC_POWER_Pin */
  GPIO_InitStruct.Pin = SEC_POWER_Pin;
  GPIO_InitStruct.Mode = GPIO_MODE_IT_RISING;
  GPIO_InitStruct.Pull = GPIO_NOPULL;
  HAL_GPIO_Init(SEC_POWER_GPIO_Port, &GPIO_InitStruct);

  /*Configure GPIO pin : DIR_ERROR_Pin */
  GPIO_InitStruct.Pin = DIR_ERROR_Pin;
  GPIO_InitStruct.Mode = GPIO_MODE_IT_RISING;
  GPIO_InitStruct.Pull = GPIO_NOPULL;
  HAL_GPIO_Init(DIR_ERROR_GPIO_Port, &GPIO_InitStruct);

  /*Configure GPIO pin : DIR_NPCM_Pin */
  GPIO_InitStruct.Pin = DIR_NPCM_Pin;
  GPIO_InitStruct.Mode = GPIO_MODE_IT_RISING_FALLING;
  GPIO_InitStruct.Pull = GPIO_NOPULL;
  HAL_GPIO_Init(DIR_NPCM_GPIO_Port, &GPIO_InitStruct);

  /* EXTI interrupt init*/
  HAL_NVIC_SetPriority(EXTI0_1_IRQn, 0, 0);
  HAL_NVIC_EnableIRQ(EXTI0_1_IRQn);

  HAL_NVIC_SetPriority(EXTI2_3_IRQn, 0, 0);
  HAL_NVIC_EnableIRQ(EXTI2_3_IRQn);

  HAL_NVIC_SetPriority(EXTI4_15_IRQn, 0, 0);
  HAL_NVIC_EnableIRQ(EXTI4_15_IRQn);

}

void Error_Handler(void)
{
  /* USER CODE BEGIN Error_Handler_Debug */
  /* User can add his own implementation to report the HAL error return state */
  __disable_irq();
  while (1)
  {
	  LED_Standby(GPIO_PIN_SET);
	  HAL_Delay(1000);
	  LED_Standby(GPIO_PIN_RESET);
	  HAL_Delay(1000);
  }
  /* USER CODE END Error_Handler_Debug */
}
